# nrf54h20_engb_sysctrl register map
Vendor: Nordic Semiconductor; Series: nRF54h; File version: 1
Registers are 32-bit, read-write, reset 0x0 unless marked. A register's access mark holds for its fields unless they carry their own. Offsets are from the block's base; [hi:lo] are bit positions; lines under a group give offsets from that group; {n}, {i} and the like mark numbered series.

## GLOBAL_EGU130 — Event generator unit
Base 0x5F92D000
{0x0+4i} TASKS_TRIGGER[{i}] (i=0..15) wo — Description collection: Trigger n for triggering the corresponding TRIGGERED[n] event
  [0] TASKS_TRIGGER — Trigger n for triggering the corresponding TRIGGERED[n] event
    1=Trigger task
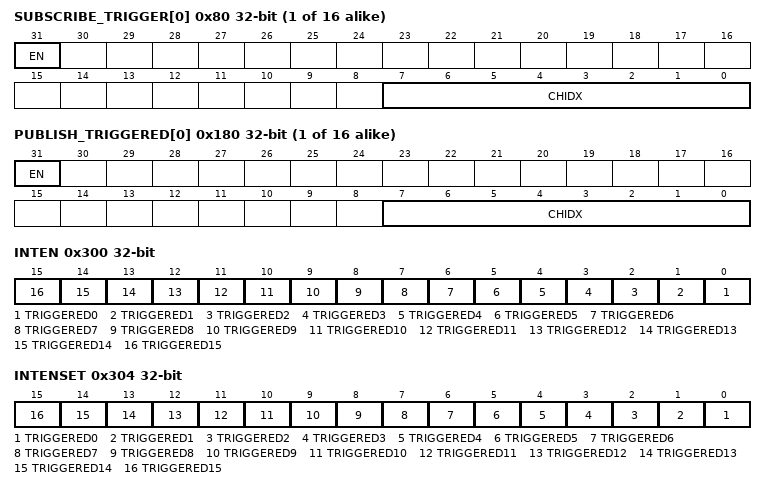
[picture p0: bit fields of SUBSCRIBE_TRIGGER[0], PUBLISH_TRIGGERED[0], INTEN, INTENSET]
{0x80+4i} SUBSCRIBE_TRIGGER[{i}] (i=0..15) — Description collection: Subscribe configuration for task TRIGGER[n]
  [31] EN
    0=Disabled (Disable subscription); 1=Enabled (Enable subscription)
  [7:0] CHIDX — DPPI channel that task TRIGGER[n] will subscribe to
{0x100+4i} EVENTS_TRIGGERED[{i}] (i=0..15) — Description collection: Event number n generated by triggering the corresponding TRIGGER[n] task
  [0] EVENTS_TRIGGERED — Event number n generated by triggering the corresponding TRIGGER[n] task
    0=NotGenerated (Event not generated); 1=Generated (Event generated)
{0x180+4i} PUBLISH_TRIGGERED[{i}] (i=0..15) — Description collection: Publish configuration for event TRIGGERED[n]
  [31] EN
    0=Disabled (Disable publishing); 1=Enabled (Enable publishing)
  [7:0] CHIDX — DPPI channel that event TRIGGERED[n] will publish to
0x300 INTEN — Enable or disable interrupt
  [all] fields
    0=Disabled; 1=Enabled
  [n] TRIGGERED{n} (n=0..15) — Enable or disable interrupt for event TRIGGERED[{n}]
0x304 INTENSET — Enable interrupt
  [all] fields
    on read: 0=Disabled (Read: Disabled); 1=Enabled (Read: Enabled) | on write: 1=Set (Enable)
  [n] TRIGGERED{n} (n=0..15) — Write '1' to enable interrupt for event TRIGGERED[{n}]
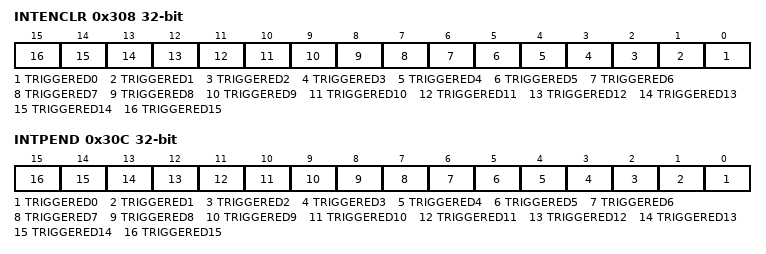
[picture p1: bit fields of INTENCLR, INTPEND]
0x308 INTENCLR — Disable interrupt
  [all] fields
    on read: 0=Disabled (Read: Disabled); 1=Enabled (Read: Enabled) | on write: 1=Clear (Disable)
  [n] TRIGGERED{n} (n=0..15) — Write '1' to disable interrupt for event TRIGGERED[{n}]
0x30C INTPEND ro — Pending interrupts
  [all] fields
    on read: 0=NotPending (Read: Not pending); 1=Pending (Read: Pending)
  [n] TRIGGERED{n} (n=0..15) — Read pending status of interrupt for event TRIGGERED[{n}]

## GLOBAL_GPIOINTERNAL — GPIO Internal
Base 0x5F939E00
0x40 LATCHCLRWAITCNT reset 0x2 — Select the number of wait cycles inserted on the bus when a LATCH register is cleared.
  [1:0] LATCHCLRWAITCNT
0x44 FORCELDETECTLOWCNT reset 0x8 — Select the number of cycles that LDETECT is forced low after clearing a LATCH register.
  [3:0] FORCELDETECTLOWCNT
0x48 RESET — Reset all GPIO registers.
  [0] RESET
    1=RESET (Trigger reset); 0=NA (No effect)
0x4C SENSECONFIGCHANGECNT reset 0x3 — Selects the number of cycles before the SENSE configuration takes effect when it is changed. Setting this register lower than the reset value can lead to unwanted LATCH set when SENSE and INPUT fields (PIN[n].CNF) are changed simultaneously.
  [2:0] SENSECONFIGCHANGECNT — Selects the number of cycles before the SENSE configuration takes effect when it is changed.
0x160 PCGC group — Unspecified
  0x00 TURNOFFAUTOCLOCKSOURCEREQ ro — No functionality
  {0x20+4j} PENALTY[{j}] (j=0..4) ro — Description collection: Penalty level for power/clock pair n
    [7:0] PENALTY — Penalty level
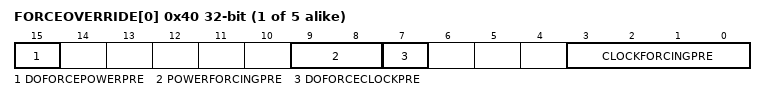
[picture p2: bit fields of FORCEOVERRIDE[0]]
  {0x40+4j} FORCEOVERRIDE[{j}] (j=0..4) ro — Description collection: Force override of power/clock pair n
    [15] DOFORCEPOWERPRE, [9:8] POWERFORCINGPRE, [7] DOFORCECLOCKPRE, [3:0] CLOCKFORCINGPRE

## GLOBAL_RESETHUB — Reset hub
Base 0x5F949000
{0x0+4i} TASKS_RESETDOMAIN[{i}] (i=0..3) wo — Description collection: Reset the domain [n], where n is domain id.
  [0] TASKS_RESETDOMAIN — Reset the domain [n], where n is domain id.
    1=Trigger task
{0x100+4i} EVENTS_DOMAINRESET[{i}] (i=0..3) — Description collection: Domain [n] was reset, where n is domain id.
  [0] EVENTS_DOMAINRESET — Domain [n] was reset, where n is domain id.
    0=NotGenerated (Event not generated); 1=Generated (Event generated)
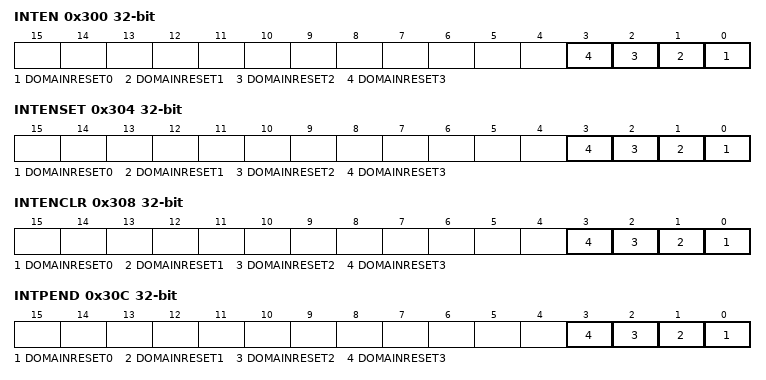
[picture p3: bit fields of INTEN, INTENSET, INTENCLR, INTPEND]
0x300 INTEN — Enable or disable interrupt
  [all] fields
    0=Disabled; 1=Enabled
  [n] DOMAINRESET{n} (n=0..3) — Enable or disable interrupt for event DOMAINRESET[{n}]
0x304 INTENSET — Enable interrupt
  [all] fields
    on read: 0=Disabled (Read: Disabled); 1=Enabled (Read: Enabled) | on write: 1=Set (Enable)
  [n] DOMAINRESET{n} (n=0..3) — Write '1' to enable interrupt for event DOMAINRESET[{n}]
0x308 INTENCLR — Disable interrupt
  [all] fields
    on read: 0=Disabled (Read: Disabled); 1=Enabled (Read: Enabled) | on write: 1=Clear (Disable)
  [n] DOMAINRESET{n} (n=0..3) — Write '1' to disable interrupt for event DOMAINRESET[{n}]
0x30C INTPEND ro — Pending interrupts
  [all] fields
    on read: 0=NotPending (Read: Not pending); 1=Pending (Read: Pending)
  [n] DOMAINRESET{n} (n=0..3) — Read pending status of interrupt for event DOMAINRESET[{n}]
0x400 RESETREAS group — Unspecified
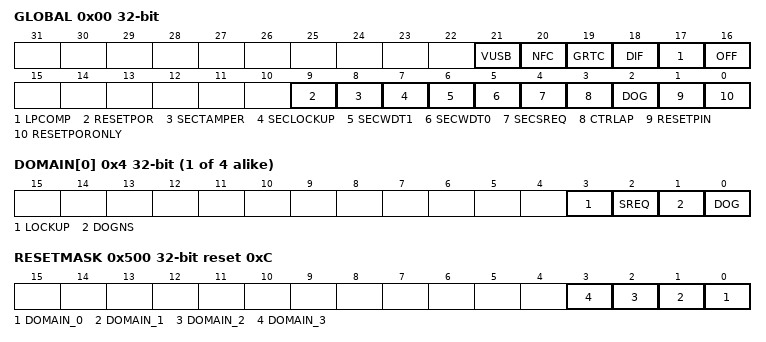
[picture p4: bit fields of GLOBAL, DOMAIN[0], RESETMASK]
  0x00 GLOBAL write-1-clears — Global reset reason.
    [all] fields
      0=NotDetected; 1=Detected
    [21] VUSB — Reset after wakeup from System OFF mode due to VBUS rising into valid range.
    [20] NFC — Reset due to wakeup from System OFF mode when wakeup is triggered by NFC field detection in sense mode.
    [19] GRTC — Reset due to wakeup from System OFF mode when wakeup is triggered by GRTC interrupt.
    [18] DIF — Reset due to wakeup from System OFF mode when wakeup is triggered by entering the debug interface mode.
    [17] LPCOMP — Reset due to wakeup from System OFF mode when wakeup is triggered by LPCOMP (Low Power Comparator).
    [16] OFF — Reset due to wakeup from System OFF mode when wakeup is triggered by DETECT signal from GPIO.
    [9] RESETPOR — Reset from power on reset (reset reason other than POR or BOR).
    [8] SECTAMPER — Reset due to secure domain tamper detected
    [7] SECLOCKUP — Reset due to secure domain lockup.
    [6] SECWDT1 — Reset due to the second instance of watchdog timer in secure domain detected.
    [5] SECWDT0 — Reset due to the first instance of watchdog timer in secure domain detected.
    [4] SECSREQ — Reset due to secure domain system reset request.
    [3] CTRLAP — Reset from CTRL-AP detected.
    [2] DOG — Reset from the SysCtrl watchdog timer detected.
    [1] RESETPIN — Reset from pin reset detected.
    [0] RESETPORONLY — Reset from power on reset (reset reason POR or BOR).
  {0x4+4j} DOMAIN[{j}] (j=0..3) write-1-clears — Description collection: Reset reason for the domain[n], where n is domain id.
    [all] fields
      0=NotDetected; 1=Detected
    [3] LOCKUP — Reset from local CPU lockup detected
    [2] SREQ — Reset from the local soft reset request detected.
    [1] DOGNS — Reset from the local non-secure watchdog timer detected
    [0] DOG — Reset from the local watchdog timer detected
0x500 RESETMASK reset 0xC — Mask the reset request for a domain by itself.
  [all] fields
    0=Mask the reset request; 1=Unmask the reset request
  [n] DOMAIN_{n} (n=0..3) — Mask the reset request for the domain[{n}], where [{n}] is domain id.
0x508 GPREGRET — General purpose retention register.
  [7:0] GPREGRET
